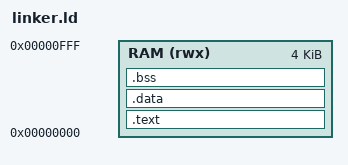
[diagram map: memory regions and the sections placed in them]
ENTRY(_start)

MEMORY
{
    RAM (rwx) : ORIGIN = 0x00000000, LENGTH = 4K
}

SECTIONS
{
    .text : {
        *(.text*)
        *(.rodata*)
    } > RAM

    .data : {
        *(.data*)
    } > RAM

    .bss : {
        *(.bss*)
        *(COMMON)
    } > RAM

    . = ORIGIN(RAM) + LENGTH(RAM);
    _stack_top = .;
}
